# AT91SAM9M11 register map
Vendor: Atmel; File version: 20130207
CPU: 
Registers are 32-bit, read-write, no defined reset value unless marked. A register's access mark holds for its fields unless they carry their own. Offsets are from the block's base; [hi:lo] are bit positions.

## DBGU — Debug Unit
Base 0xFFFFEE00; register names take the prefix DBGU_
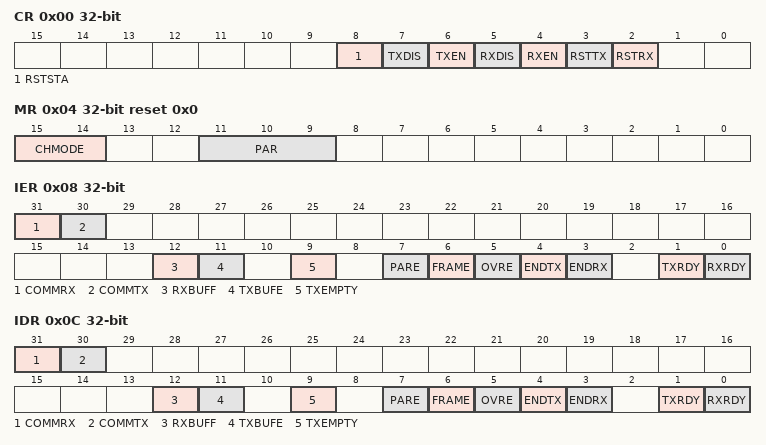
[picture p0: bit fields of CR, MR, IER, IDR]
0x00 CR wo — Control Register
  [8] RSTSTA — Reset Status Bits
  [7] TXDIS — Transmitter Disable
  [6] TXEN — Transmitter Enable
  [5] RXDIS — Receiver Disable
  [4] RXEN — Receiver Enable
  [3] RSTTX — Reset Transmitter
  [2] RSTRX — Reset Receiver
0x04 MR reset 0x0 — Mode Register
  [15:14] CHMODE — Channel Mode
  [11:9] PAR — Parity Type
0x08 IER wo — Interrupt Enable Register
  [31] COMMRX — Enable COMMRX (from ARM) Interrupt
  [30] COMMTX — Enable COMMTX (from ARM) Interrupt
  [12] RXBUFF — Enable Buffer Full Interrupt
  [11] TXBUFE — Enable Buffer Empty Interrupt
  [9] TXEMPTY — Enable TXEMPTY Interrupt
  [7] PARE — Enable Parity Error Interrupt
  [6] FRAME — Enable Framing Error Interrupt
  [5] OVRE — Enable Overrun Error Interrupt
  [4] ENDTX — Enable End of Transmit Interrupt
  [3] ENDRX — Enable End of Receive Transfer Interrupt
  [1] TXRDY — Enable TXRDY Interrupt
  [0] RXRDY — Enable RXRDY Interrupt
0x0C IDR wo — Interrupt Disable Register
  [31] COMMRX — Disable COMMRX (from ARM) Interrupt
  [30] COMMTX — Disable COMMTX (from ARM) Interrupt
  [12] RXBUFF — Disable Buffer Full Interrupt
  [11] TXBUFE — Disable Buffer Empty Interrupt
  [9] TXEMPTY — Disable TXEMPTY Interrupt
  [7] PARE — Disable Parity Error Interrupt
  [6] FRAME — Disable Framing Error Interrupt
  [5] OVRE — Disable Overrun Error Interrupt
  [4] ENDTX — Disable End of Transmit Interrupt
  [3] ENDRX — Disable End of Receive Transfer Interrupt
  [1] TXRDY — Disable TXRDY Interrupt
  [0] RXRDY — Disable RXRDY Interrupt
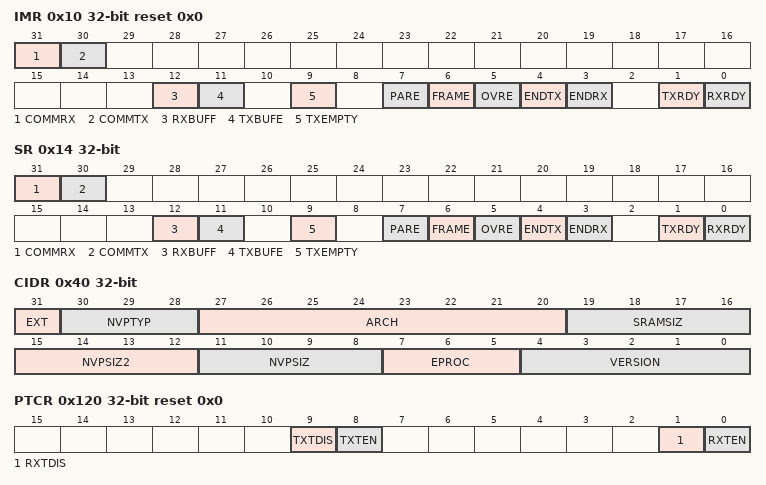
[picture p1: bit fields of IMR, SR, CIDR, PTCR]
0x10 IMR ro reset 0x0 — Interrupt Mask Register
  [31] COMMRX — Mask COMMRX Interrupt
  [30] COMMTX — Mask COMMTX Interrupt
  [12] RXBUFF — Mask RXBUFF Interrupt
  [11] TXBUFE — Mask TXBUFE Interrupt
  [9] TXEMPTY — Mask TXEMPTY Interrupt
  [7] PARE — Mask Parity Error Interrupt
  [6] FRAME — Mask Framing Error Interrupt
  [5] OVRE — Mask Overrun Error Interrupt
  [4] ENDTX — Mask End of Transmit Interrupt
  [3] ENDRX — Mask End of Receive Transfer Interrupt
  [1] TXRDY — Disable TXRDY Interrupt
  [0] RXRDY — Mask RXRDY Interrupt
0x14 SR ro — Status Register
  [31] COMMRX — Debug Communication Channel Read Status
  [30] COMMTX — Debug Communication Channel Write Status
  [12] RXBUFF — Receive Buffer Full
  [11] TXBUFE — Transmission Buffer Empty
  [9] TXEMPTY — Transmitter Empty
  [7] PARE — Parity Error
  [6] FRAME — Framing Error
  [5] OVRE — Overrun Error
  [4] ENDTX — End of Transmitter Transfer
  [3] ENDRX — End of Receiver Transfer
  [1] TXRDY — Transmitter Ready
  [0] RXRDY — Receiver Ready
0x18 RHR ro reset 0x0 — Receive Holding Register
  [7:0] RXCHR — Received Character
0x1C THR wo — Transmit Holding Register
  [7:0] TXCHR — Character to be Transmitted
0x20 BRGR reset 0x0 — Baud Rate Generator Register
  [15:0] CD — Clock Divisor
0x40 CIDR ro — Chip ID Register
  [31] EXT — Extension Flag
  [30:28] NVPTYP — Nonvolatile Program Memory Type
  [27:20] ARCH — Architecture Identifier
  [19:16] SRAMSIZ — Internal SRAM Size
  [15:12] NVPSIZ2
  [11:8] NVPSIZ — Nonvolatile Program Memory Size
  [7:5] EPROC — Embedded Processor
  [4:0] VERSION — Version of the Device
0x44 EXID ro — Chip ID Extension Register
  [31:0] EXID — Chip ID Extension
0x48 FNR reset 0x0 — Force NTRST Register
  [0] FNTRST — Force NTRST
0x100 RPR reset 0x0 — Receive Pointer Register
  [31:0] RXPTR
0x104 RCR reset 0x0 — Receive Counter Register
  [15:0] RXCTR
0x108 TPR reset 0x0 — Transmit Pointer Register
  [31:0] TXPTR — Transmit Counter Register
0x10C TCR reset 0x0 — Transmit Counter Register
  [15:0] TXCTR
0x110 RNPR reset 0x0 — Receive Next Pointer Register
  [31:0] RXNPTR — Receive Next Pointer
0x114 RNCR reset 0x0 — Receive Next Counter Register
  [15:0] RXNCTR — Receive Next Counter
0x118 TNPR reset 0x0 — Transmit Next Pointer Register
  [31:0] TXNPTR — Transmit Next Pointer
0x11C TNCR reset 0x0 — Transmit Next Counter Register
  [15:0] TXNCTR — Transmit Counter Next
0x120 PTCR wo reset 0x0 — Transfer Control Register
  [9] TXTDIS — Transmitter Transfer Disable
  [8] TXTEN — Transmitter Transfer Enable
  [1] RXTDIS — Receiver Transfer Disable
  [0] RXTEN — Receiver Transfer Enable
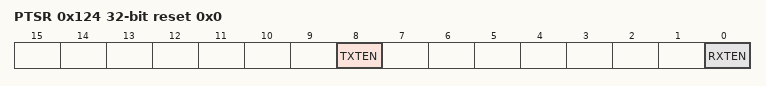
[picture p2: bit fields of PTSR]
0x124 PTSR ro reset 0x0 — Transfer Status Register
  [8] TXTEN — Transmitter Transfer Enable
  [0] RXTEN — Receiver Transfer Enable
